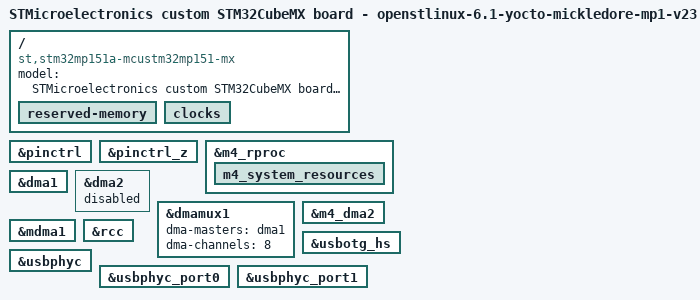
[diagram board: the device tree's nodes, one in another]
// SPDX-License-Identifier: (GPL-2.0-or-later OR BSD-3-Clause)
/*
 * Copyright (C) 2023, STMicroelectronics - All Rights Reserved
 * Author: STM32CubeMX code generation for STMicroelectronics.
 */

/* For more information on Device Tree configuration, please refer to
 * https://wiki.st.com/stm32mpu/wiki/Category:Device_tree_configuration
 */

/dts-v1/;
#include <dt-bindings/pinctrl/stm32-pinfunc.h>

#include "stm32mp151.dtsi"
#include "stm32mp15xa.dtsi"
#include "stm32mp15xxac-pinctrl.dtsi"
#include "stm32mp15-m4-srm.dtsi"

/* USER CODE BEGIN includes */
/* USER CODE END includes */

/ {
	model = "STMicroelectronics custom STM32CubeMX board - openstlinux-6.1-yocto-mickledore-mp1-v23.06.21";
	compatible = "st,stm32mp151a-mcustm32mp151-mx", "st,stm32mp151";

	/* !!! log : Warning - no DDR config found: 'memory' node not generated  !!! */

	/*
	memory@??? {
		reg = < ??? >;
	};
	*/

	reserved-memory {
		#address-cells = <1>;
		#size-cells = <1>;
		ranges;

		/* USER CODE BEGIN reserved-memory */
		/* USER CODE END reserved-memory */
	};

	/* USER CODE BEGIN root */
	/* USER CODE END root */

	clocks{

		/* USER CODE BEGIN clocks */
		/* USER CODE END clocks */
	};

}; /*root*/

&pinctrl {

	/* USER CODE BEGIN pinctrl */
	/* USER CODE END pinctrl */
};

&pinctrl_z {

	/* USER CODE BEGIN pinctrl_z */
	/* USER CODE END pinctrl_z */
};

&m4_rproc{
	status = "okay";

	/* USER CODE BEGIN m4_rproc */
	/* USER CODE END m4_rproc */

	m4_system_resources{
		status = "okay";

		/* USER CODE BEGIN m4_system_resources */
		/* USER CODE END m4_system_resources */
	};
};

&dma1{
	status = "okay";

	/* USER CODE BEGIN dma1 */
	/* USER CODE END dma1 */
};

&dma2{
	status = "disabled";

	/* USER CODE BEGIN dma2 */
	/* USER CODE END dma2 */
};

&dmamux1{
	status = "okay";

	dma-masters = <&dma1>;
	dma-channels = <8>;

	/* USER CODE BEGIN dmamux1 */
	/* USER CODE END dmamux1 */
};

&m4_dma2{
	status = "okay";

	/* USER CODE BEGIN m4_dma2 */
	/* USER CODE END m4_dma2 */
};

&mdma1{
	status = "okay";

	/* USER CODE BEGIN mdma1 */
	/* USER CODE END mdma1 */
};

&rcc{
	status = "okay";

	/* USER CODE BEGIN rcc */
	/* USER CODE END rcc */
};

&usbotg_hs{
	status = "okay";

	/* USER CODE BEGIN usbotg_hs */
	/* USER CODE END usbotg_hs */
};

&usbphyc{
	status = "okay";

	/* USER CODE BEGIN usbphyc */
	/* USER CODE END usbphyc */
};

&usbphyc_port0{
	status = "okay";

	/* USER CODE BEGIN usbphyc_port0 */
	/* USER CODE END usbphyc_port0 */
};

&usbphyc_port1{
	status = "okay";

	/* USER CODE BEGIN usbphyc_port1 */
	/* USER CODE END usbphyc_port1 */
};

/* USER CODE BEGIN addons */
/* USER CODE END addons */

